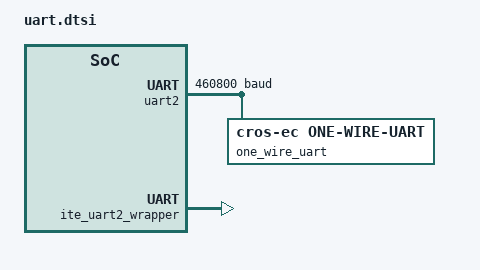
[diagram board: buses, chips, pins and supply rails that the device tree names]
/* Copyright 2023 The ChromiumOS Authors
 * Use of this source code is governed by a BSD-style license that can be
 * found in the LICENSE file.
 */

&uart2 {
	status = "okay";
	current-speed = <460800>;
	clock-frequency = <1843200>;

	one_wire_uart: one-wire-uart {
		compatible = "cros-ec,one-wire-uart";
	};
};

&ite_uart2_wrapper {
	status = "okay";
	pinctrl-0 = <&uart2_rx_gpf0_default
		     &uart2_tx_gpf1_default>;
	pinctrl-names = "default";
};
